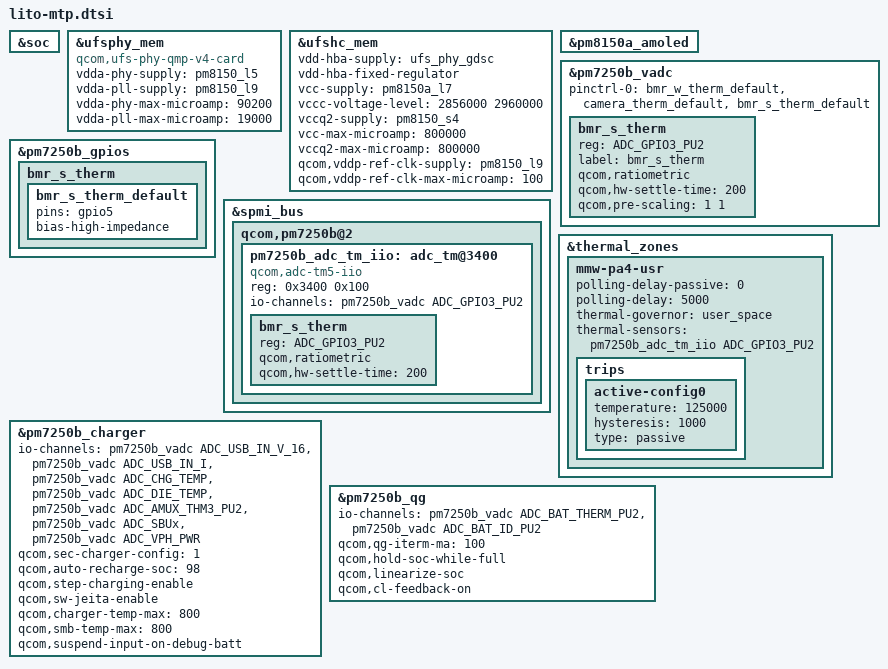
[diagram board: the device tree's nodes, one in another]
#include "lito-audio-overlay.dtsi"
#include "lito-pmic-overlay.dtsi"

&soc {

};

&ufsphy_mem {
	compatible = "qcom,ufs-phy-qmp-v4-card";

	vdda-phy-supply = <&pm8150_l5>;
	vdda-pll-supply = <&pm8150_l9>;
	vdda-phy-max-microamp = <90200>;
	vdda-pll-max-microamp = <19000>;

	status = "ok";
};

&ufshc_mem {
	vdd-hba-supply = <&ufs_phy_gdsc>;
	vdd-hba-fixed-regulator;
	vcc-supply = <&pm8150a_l7>;
	vccc-voltage-level = <2856000 2960000>;
	vccq2-supply = <&pm8150_s4>;
	vcc-max-microamp = <800000>;
	vccq2-max-microamp = <800000>;

	qcom,vddp-ref-clk-supply = <&pm8150_l9>;
	qcom,vddp-ref-clk-max-microamp = <100>;

	status = "ok";
};

&pm8150a_amoled {
	status = "ok";
};

&pm7250b_vadc {
	pinctrl-0 = <
		&bmr_w_therm_default
		&camera_therm_default
		&bmr_s_therm_default
	>;

	bmr_s_therm {
		reg = <ADC_GPIO3_PU2>;
		label = "bmr_s_therm";
		qcom,ratiometric;
		qcom,hw-settle-time = <200>;
		qcom,pre-scaling = <1 1>;
	};
};

&pm7250b_gpios {
	bmr_s_therm {
		bmr_s_therm_default: bmr_s_therm_default {
			pins = "gpio5";
			bias-high-impedance;
		};
	};
};

&spmi_bus {
	qcom,pm7250b@2 {
		pm7250b_adc_tm_iio: adc_tm@3400 {
			compatible = "qcom,adc-tm5-iio";
			reg = <0x3400 0x100>;
			#thermal-sensor-cells = <1>;
			io-channels = <&pm7250b_vadc ADC_GPIO3_PU2>;

			bmr_s_therm {
				reg = <ADC_GPIO3_PU2>;
				qcom,ratiometric;
				qcom,hw-settle-time = <200>;
			};
		};
	};
};

&thermal_zones {
	mmw-pa4-usr {
		polling-delay-passive = <0>;
		polling-delay = <5000>;
		thermal-governor = "user_space";
		thermal-sensors = <&pm7250b_adc_tm_iio ADC_GPIO3_PU2>;
		trips {
			active-config0 {
				temperature = <125000>;
				hysteresis = <1000>;
				type = "passive";
			};
		};
	};
};

&pm7250b_charger {
	status = "ok";
	io-channels = <&pm7250b_vadc ADC_USB_IN_V_16>,
		      <&pm7250b_vadc ADC_USB_IN_I>,
		      <&pm7250b_vadc ADC_CHG_TEMP>,
		      <&pm7250b_vadc ADC_DIE_TEMP>,
		      <&pm7250b_vadc ADC_AMUX_THM3_PU2>,
		      <&pm7250b_vadc ADC_SBUx>,
		      <&pm7250b_vadc ADC_VPH_PWR>;
	io-channel-names = "usb_in_voltage",
			   "usb_in_current",
			   "chg_temp",
			   "die_temp",
			   "conn_temp",
			   "sbux_res",
			   "vph_voltage";
	qcom,sec-charger-config = <1>;
	qcom,auto-recharge-soc = <98>;
	qcom,step-charging-enable;
	qcom,sw-jeita-enable;
	qcom,charger-temp-max = <800>;
	qcom,smb-temp-max = <800>;
	qcom,suspend-input-on-debug-batt;
};

&pm7250b_qg {
	status = "ok";
	io-channels = <&pm7250b_vadc ADC_BAT_THERM_PU2>,
		      <&pm7250b_vadc ADC_BAT_ID_PU2>;
	io-channel-names = "batt-therm",
			   "batt-id";
	qcom,qg-iterm-ma = <100>;
	qcom,hold-soc-while-full;
	qcom,linearize-soc;
	qcom,cl-feedback-on;
};
